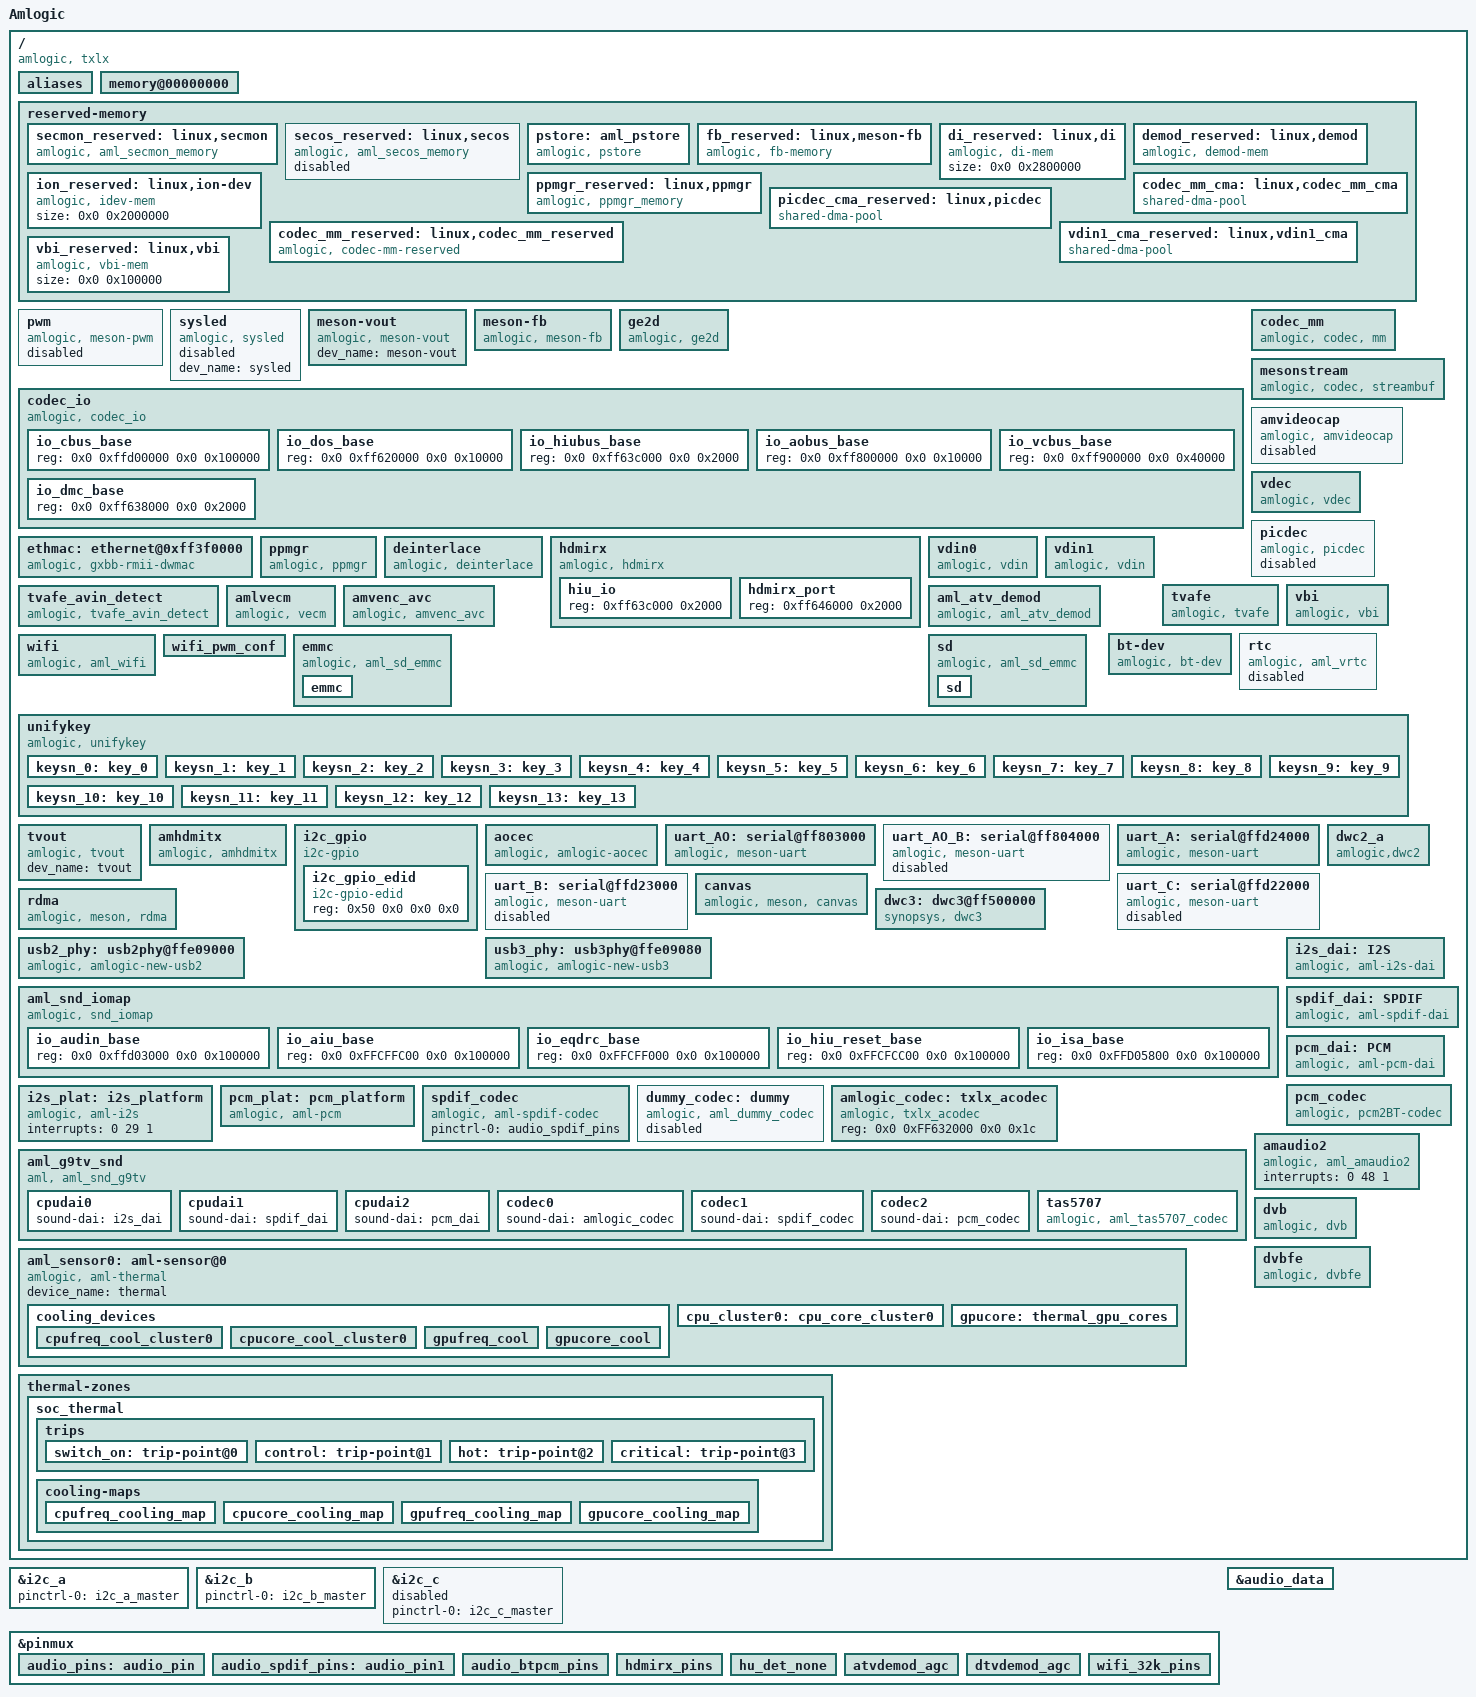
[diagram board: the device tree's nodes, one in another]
/*
 * arch/arm64/boot/dts/amlogic/txlx_t962e_r311.dts
 *
 * Copyright (C) 2017 Amlogic, Inc. All rights reserved.
 *
 * This program is free software; you can redistribute it and/or modify
 * it under the terms of the GNU General Public License as published by
 * the Free Software Foundation; either version 2 of the License, or
 * (at your option) any later version.
 *
 * This program is distributed in the hope that it will be useful, but WITHOUT
 * ANY WARRANTY; without even the implied warranty of MERCHANTABILITY or
 * FITNESS FOR A PARTICULAR PURPOSE.  See the GNU General Public License for
 * more details.
 *
*/

/dts-v1/;

#include <dt-bindings/interrupt-controller/arm-gic.h>
#include <dt-bindings/clock/txlx.h>
#include <dt-bindings/gpio/txlx.h>
#include <dt-bindings/gpio/gpio.h>
#include <dt-bindings/reset/aml_txlx.h>
#include <dt-bindings/pwm/pwm.h>
#include <dt-bindings/pwm/meson.h>

#include "mesontxlx.dtsi"
#include "partition_tv.dtsi"

/ {
	model = "Amlogic";
	compatible = "amlogic, txlx";
	interrupt-parent = <&gic>;
	#address-cells = <2>;
	#size-cells = <2>;

	aliases {
		serial0 = &uart_AO;
		serial1 = &uart_A;
		serial2 = &uart_B;
		serial3 = &uart_C;
		serial4 = &uart_AO_B;
	};

	memory@00000000 {
		device_type = "memory";
		linux,usable-memory = <0x0 0x100000 0x0 0x7ff00000>;
	};

	reserved-memory {
		#address-cells = <2>;
		#size-cells = <2>;
		ranges;
		/* global autoconfigured region for contiguous allocations */
		secmon_reserved:linux,secmon {
			compatible = "amlogic, aml_secmon_memory";
			reg = <0x0 0x10000000 0x0 0x200000>;
			no-map;
		};

		secos_reserved:linux,secos {
			status = "disable";
			compatible = "amlogic, aml_secos_memory";
			reg = <0x0 0x05300000 0x0 0x2000000>;
			no-map;
		};

		pstore:aml_pstore {
			compatible = "amlogic, pstore";
			reg = <0x0 0x07300000 0x0 0x100000>;
			no-map;
		};

		fb_reserved:linux,meson-fb {
			compatible = "amlogic, fb-memory";
			size = <0x0 0x2000000>;
			no-map;
		};
		/*di reserved mem*/
		di_reserved:linux,di {
			compatible = "amlogic, di-mem";
			/* buffer_size = 3621952(yuv422 8bit) | 4736064(yuv422 10bit) | 4179008(yuv422 10bit full pack mode) */
			/** 10x3621952=34.6M(0x23) support 8bit **/
			/** 10x4736064=45.2M(0x2e) support 12bit **/
			/** 10x4179008=40M(0x28) support 10bit **/
			size = <0x0 0x2800000>;
			//no-map;
		};
		/*di CMA pool */
		//di_cma_reserved:linux,di_cma {
			//compatible = "shared-dma-pool";
			//reusable;
			/* buffer_size = 3621952(yuv422 8bit) | 4736064(yuv422 10bit) | 4179008(yuv422 10bit full pack mode) */
			/** 10x3621952=34.6M(0x23) support 8bit **/
			/** 10x4736064=45.2M(0x2e) support 12bit **/
			/** 10x4179008=40M(0x28) support 10bit **/
			//size = <0x0 0x02800000>;
			//alignment = <0x0 0x400000>;
		//};
		demod_reserved:linux,demod {
			compatible = "amlogic, demod-mem";
			size = <0x0 0x600000>; //20m
			multi-use;
			//no-map;
		};

		ion_reserved:linux,ion-dev {
			compatible = "amlogic, idev-mem";
			size = <0x0 0x2000000>;
		};

		/*  POST PROCESS MANAGER */
		ppmgr_reserved:linux,ppmgr {
			compatible = "amlogic, ppmgr_memory";
			size = <0x0 0x0>;
			multi-use;
		};

		codec_mm_cma:linux,codec_mm_cma {
			compatible = "shared-dma-pool";
			reusable;
			size = <0x0 0xbc00000>;
			alignment = <0x0 0x400000>;
			linux,contiguous-region;
		};

		picdec_cma_reserved:linux,picdec {
			compatible = "shared-dma-pool";
			reusable;
			size = <0x0 0x0>;
			alignment = <0x0 0x0>;
			linux,contiguous-region;
		};

		/* codec shared reserved */
		codec_mm_reserved:linux,codec_mm_reserved {
			compatible = "amlogic, codec-mm-reserved";
			size = <0x0 0x4100000>;
			alignment = <0x0 0x100000>;
 			//no-map;
		};
		/*  vdin0 CMA pool */
		//vdin0_cma_reserved:linux,vdin0_cma {
		//	compatible = "shared-dma-pool";
		//	linux,phandle = <4>;
		//	reusable;
			/* 3840x2160x2x4  =64+4 M */
		//	size = <0x0 0x04400000>;
		//	alignment = <0x0 0x400000>;
		//};
		/*  vdin1 CMA pool */
		vdin1_cma_reserved:linux,vdin1_cma {
			compatible = "shared-dma-pool";
			linux,phandle = <5>;
			reusable;
			/* 1920x1080x2x4  =16+4 M */
			size = <0x0 0x01400000>;
			alignment = <0x0 0x400000>;
		};
		/*  tvafe CMA pool */
		//tvafe_cma_reserved:linux,tvafe_cma {
		//	compatible = "shared-dma-pool";
		//	linux,phandle = <6>;
		//	reusable;
			/* 5 M */
		//	size = <0x0 0x00800000>;
		//	alignment = <0x0 0x400000>;
		//};
		/*vbi reserved mem*/
		vbi_reserved:linux,vbi {
			compatible = "amlogic, vbi-mem";
			size = <0x0 0x100000>;
		};
	};

	pwm {
		compatible = "amlogic, meson-pwm";
		status = "disabled";
		pwm-outputs 	= <PWM_A>,<PWM_B>,<PWM_C>,<PWM_D>,
			      	  <PWM_E>,<PWM_F>,<PWM_AO_A>,<PWM_AO_B>;
		pwm-outputs-new = <PWM_A>,<PWM_B>,<PWM_C>,<PWM_D>,
				  <PWM_E>,<PWM_F>,<PWM_AO_A>,<PWM_AO_B>,
			          <PWM_A2>,<PWM_B2>,<PWM_C2>,<PWM_D2>,
			          <PWM_E2>,<PWM_F2>,<PWM_AO_A2>,<PWM_AO_B2>;
		reg = <0x0 0xc1108550 0x0 0x30>,
		      <0x0 0xc8100550  0x0 0x10>;
		clocks = <&clock CLK_XTAL>,
			 <&clock CLK_VID_PLL>,
			 <&clock CLK_FPLL_DIV4>,
			 <&clock CLK_FPLL_DIV3>;
		clock-names = "xtal",
			      "vid_pll_clk",
			      "fclk_div4",
			      "fclk_div3";
		clock-select = <XTAL_CLK>,<XTAL_CLK>,<XTAL_CLK>,<XTAL_CLK>,
			       	   <XTAL_CLK>,<XTAL_CLK>,<XTAL_CLK>,<XTAL_CLK>;
		clock-select-new = <XTAL_CLK>,<XTAL_CLK>,<XTAL_CLK>,<XTAL_CLK>,
		                   <XTAL_CLK>,<XTAL_CLK>,<XTAL_CLK>,<XTAL_CLK>,
		                   <XTAL_CLK>,<XTAL_CLK>,<XTAL_CLK>,<XTAL_CLK>,
		                   <XTAL_CLK>,<XTAL_CLK>,<XTAL_CLK>,<XTAL_CLK>;
		                   /*all channels use the default clock source XTAL_CLK*/
		                   /*and you can shoose it in file dt-bindings/pwm/meson.h*/
	};

	sysled {
		compatible = "amlogic, sysled";
		dev_name = "sysled";
		status = "disable";
		//led_gpio = <&gpio GPIODV_24 GPIO_ACTIVE_LOW>;
	};

	meson-vout {
		compatible = "amlogic, meson-vout";
		dev_name = "meson-vout";
		status = "okay";
	};

	meson-fb {
		compatible = "amlogic, meson-fb";
		memory-region = <&fb_reserved>;
		dev_name = "meson-fb";
		status = "okay";
		interrupts = <0 3 1
			0 89 1>;
		interrupt-names = "viu-vsync", "rdma";
		mem_size = <0x01800000 0x00100000>; /* fb0/fb1 memory size */
		display_mode_default = "1080p60hz";
		scale_mode = <1>; /** 0:VPU free scale 1:OSD free scale 2:OSD super scale */
		display_size_default = <1920 1080 1920 3240 32>; //1920*1080*4*3 = 0x17BB000
		pxp_mode = <1>; /** 0:normal mode 1:pxp mode */
	};

	ge2d {
		compatible = "amlogic, ge2d";
		dev_name = "ge2d";
		status = "okay";
		interrupts = <0 150 1>;
		interrupt-names = "ge2d";
		clocks = <&clock CLK_VAPB_0>,
			<&clock CLK_GE2D>;
		clock-names = "clk_vapb_0",
				"clk_ge2d";
		resets = <&clock GCLK_IDX_GE2D>;
		reset-names = "ge2d";
		reg = <0x0 0xff940000 0x0 0x10000>;
	};

	codec_io {
		compatible = "amlogic, codec_io";
		status = "okay";
		#address-cells=<2>;
		#size-cells=<2>;
		ranges;
		io_cbus_base{
			reg = <0x0 0xffd00000 0x0 0x100000>;
		};
		io_dos_base{
			reg = <0x0 0xff620000 0x0 0x10000>;
		};
		io_hiubus_base{
			reg = <0x0 0xff63c000 0x0 0x2000>;
		};
		io_aobus_base{
			reg = <0x0 0xff800000 0x0 0x10000>;
		};
		io_vcbus_base{
			reg = <0x0 0xff900000 0x0 0x40000>;
		};
		io_dmc_base{
			reg = <0x0 0xff638000 0x0 0x2000>;
		};
	};

	codec_mm {
			compatible = "amlogic, codec, mm";
			memory-region = <&codec_mm_cma &codec_mm_reserved>;
			dev_name = "codec_mm";
			status = "okay";
	};

	ethmac: ethernet@0xff3f0000 {
			compatible = "amlogic, gxbb-rmii-dwmac";
			reg = <0x0 0xff3f0000 0x0 0x10000
			0x0 0xff634540 0x0 0x8
			0x0 0xff634558 0x0 0xc>;
			interrupts = <0 8 1
						  0 9 1>;
			phy-mode= "rmii";
			mc_val = <0x1804>;
			resets = <&clock GCLK_IDX_ETHERNET>;
			reset-names = "ethpower";
			interrupt-names = "macirq",
							  "phyirq";
			clocks = <&clock CLK_81>;
			clock-names = "ethclk81";
			internal_phy=<1>;
			wol=<0>;
	};
	mesonstream {
		compatible = "amlogic, codec, streambuf";
		dev_name = "mesonstream";
		status = "okay";
		resets = <&clock GCLK_IDX_U_PARSER_TOP
			&clock GCLK_IDX_VPU_INTR
			&clock GCLK_IDX_DEMUX
			&clock GCLK_IDX_DOS>;
		reset-names = "parser_top",
			"vpu_intr",
			"demux",
			"vdec";
	};

	amvideocap {
		compatible = "amlogic, amvideocap";
		dev_name = "amvideocap.0";
		status = "disabled";
		max_size = <8>;//8M
	};

	vdec {
		compatible = "amlogic, vdec";
		dev_name = "vdec.0";
		status = "okay";
		interrupts = <0 3 1
			0 23 1
			0 32 1
			0 43 1
			0 44 1
			0 45 1>;
		interrupt-names = "vsync",
			"demux",
			"parser",
			"mailbox_0",
			"mailbox_1",
			"mailbox_2";
	};

	picdec {
		   compatible = "amlogic, picdec";
		   memory-region = <&picdec_cma_reserved>;
		   dev_name = "picdec";
		   status = "disabled";
	};

	ppmgr {
		compatible = "amlogic, ppmgr";//to match of_device_id's compatible member
		memory-region = <&ppmgr_reserved>;
		dev_name = "ppmgr";
		status = "okay";
	};

	deinterlace {
		compatible = "amlogic, deinterlace";
		status = "okay";
		flag_cma = <0>;/*0:use reserved;1:use cma*/
		memory-region = <&di_reserved>;
		//memory-region = <&di_cma_reserved>;
		interrupts = <0 46 1
				0 6 1>;
		interrupt-names = "de_irq",
				"timerc";
		clocks = <&clock CLK_FPLL_DIV4>,
			<&clock CLK_VPU_CLKB_TMP>,
			<&clock CLK_VPU_CLKB>;
		clock-names = "fclk_div4", "cts_vpu_clkb_tmp", "cts_vpu_clkb";
		/* nr_size(byte) = 1920*544*2(yuv422 8bit) | 2944*544*2*8(yuv422 10bit) | 2432*544*2(yuv422 10bit full pack mode) */
		/* mtn_size(byte) = 2048*544/2 */
		/* count_size(byte) = 2048*544/2 */
		/* mv_size(byte) = 1920*544*2/5 */
		/* mc_size(byte) = 544*2 */
		/* buffer_size = nr_size + mtn_size + count_size + mv_size + mc_size */
		/* buffer_size = 3621952(yuv422 8bit) | 4736064(yuv422 10bit) | 4179008(yuv422 10bit full pack mode) */
		buffer-size = <4179008>;
		hw-version = <2>;
		/* reserve-iomap = "true"; */
		/* if enable nr10bit, set nr10bit-surpport to 1 */
		nr10bit-surpport = <1>;
	};

	hdmirx {
		compatible = "amlogic, hdmirx";
		#address-cells=<1>;
		#size-cells=<1>;
		dev_name = "hdmirx";
		status = "okay";
		pinctrl-names = "hdmirx_pins","hu_det_none";
		pinctrl-0 = <&hdmirx_pins>;
		pinctrl-1 = <&hu_det_none>;
		rx_port_maps = <0x3120>;
		repeat = <0>;
		interrupts = <0 56 1>;
		clocks = <&clock CLK_HDMIRX_MODET_CLK>,
			   <&clock CLK_HDMIRX_CFG_CLK>,
			   <&clock CLK_HDMIRX_ACR_REF_CLK>,
			   <&clock CLK_HDMIRX_AUDMEAS_CLK>,
			   <&clock CLK_XTAL>,
			   <&clock CLK_FPLL_DIV5>,
			   <&clock CLK_AUD_PLL2FS>,
			   <&clock CLK_AUD_PLL4FS>,
			   <&clock CLK_AUD_OUT>;
		clock-names = "hdmirx_modet_clk",
					"hdmirx_cfg_clk",
					"hdmirx_acr_ref_clk",
					"hdmirx_audmeas_clk",
					"xtal",
					"fclk_div5",
					"hdmirx_aud_pll2fs",
					"hdmirx_aud_pll4f",
					"clk_aud_out";
		hdmirx_id = <0>;
		en_4k_2_2k = <0>;
		hiu_io{
			reg = <0xff63c000 0x2000>;
		};
		hdmirx_port{
			reg = <0xff646000 0x2000>;
		};
        };

	vdin0 {
		compatible = "amlogic, vdin";
		/*memory-region = <&vdin0_cma_reserved>;*/
		dev_name = "vdin0";
		status = "okay";
		reserve-iomap = "true";
		flag_cma = <1>;/*1:share with codec_mm;2:cma alone*/
		/*MByte, if 10bit disable: 64M(YUV422), if 10bit enable: 64*1.5 = 96M(YUV422)
		*if support 4K2K-YUV444-10bit-WR:3840*2160*4*4 ~= 128M
		*if support 4K2K-YUV422-10bit-wr:3840*2160*3*4 ~= 96M
		*if support 4K2K-YUV422-8BIT-WR:3840*2160*2*4 ~= 64M
		*if support 1080p-YUV422-8BIT-WR:1920*1080*2*4 ~= 16M*/
		cma_size = <96>;
		interrupts = <0 83 1>;
		rdma-irq = <2>;
		clocks = <&clock CLK_FPLL_DIV5>,
			<&clock CLK_VDIN_MEAS_CLK>;
		clock-names = "fclk_div5", "cts_vdin_meas_clk";
		vdin_id = <0>;
		/*vdin write mem color depth support:
		*bit0:support 8bit
		*bit1:support 9bit
		*bit2:support 10bit
		*bit3:support 12bit
		*bit4:support yuv422 10bit full pack mode (from txl new add)*/
		tv_bit_mode = <21>;
	};
	vdin1 {
		compatible = "amlogic, vdin";
		memory-region = <&vdin1_cma_reserved>;
		dev_name = "vdin1";
		status = "okay";
		reserve-iomap = "true";
		flag_cma = <0>;/*1:share with codec_mm;0:cma alone*/
		interrupts = <0 85 1>;
		rdma-irq = <4>;
		clocks = <&clock CLK_FPLL_DIV5>,
			<&clock CLK_VDIN_MEAS_CLK>;
		clock-names = "fclk_div5", "cts_vdin_meas_clk";
		vdin_id = <1>;
		/*vdin write mem color depth support:
		*bit0:support 8bit
		*bit1:support 9bit
		*bit2:support 10bit
		*bit3:support 12bit*/
		tv_bit_mode = <1>;
	};
	tvafe {
		compatible = "amlogic, tvafe";
		/*memory-region = <&tvafe_cma_reserved>;*/
		dev_name = "tvafe";
		status = "okay";
		flag_cma = <1>;/*1:share with codec_mm;0:cma alone*/
		cma_size = <5>;/*MByte*/
		reg = <0x0 0xff642000 0x0 0x2000>;/*tvafe reg base*/
		reserve-iomap = "true";
		tvafe_id = <0>;
		pinctrl-names = "default";
		tvafe_pin_mux = < /*!!particular sequence, no more and no less!!!*/
                        3       /*// TVAFE_CVBS_IN2,  //CVBS_IN0 = 0,*/
                        1       /*// TVAFE_CVBS_IN0,    //CVBS_IN1,*/
                        2       /*// TVAFE_CVBS_IN1,  //CVBS_IN2*/
                        4       /*// TVAFE_CVBS_IN3,    //CVBS_IN3,*/
		>;
	};
	vbi {
		compatible = "amlogic, vbi";
		memory-region = <&vbi_reserved>;
		dev_name = "vbi";
		status = "okay";
		interrupts = <0 83 1>;
		reserve-iomap = "true";
	};
	tvafe_avin_detect {
		compatible = "amlogic, tvafe_avin_detect";
		dev_name = "tvafe_avin_detect";
		status = "okay";
		device_mask = <1>;/*bit0:ch1;bit1:ch2*/
		interrupts = <0 12 1>,
						<0 13 1>;
	};
	amlvecm {
		compatible = "amlogic, vecm";
		dev_name = "aml_vecm";
		status = "okay";
		gamma_en = <1>;/*1:enabel ;0:disable*/
		wb_en = <1>;/*1:enabel ;0:disable*/
		cm_en = <1>;/*1:enabel ;0:disable*/
	};

	amvenc_avc {
		compatible = "amlogic, amvenc_avc";
		//memory-region = <&amvenc_avc_reserved>;
		//memory-region = <&avc_cma_reserved>;
		dev_name = "amvenc_avc";
		status = "okay";
		interrupts = <0 45 1>;
		interrupt-names = "mailbox_2";
	};

	aml_atv_demod {
		compatible = "amlogic, aml_atv_demod";
		dev_name = "aml_atv_demod";
		status = "okay";
		//pinctrl-names="atvdemod_agc";
		//pinctrl-0=<&atvdemod_agc>;
		reg = <0x0 0xff640000 0x0 0x2000
			   0x0 0xff648000 0x0 0x2000>;
		reg_23cf = <0x88188832>;/*default:0x88188832;r840 on haier:0x48188832*/
	};

	bt-dev{
		compatible = "amlogic, bt-dev";
		dev_name = "bt-dev";
		status = "okay";
		gpio_reset = <&gpio_ao GPIOAO_13 GPIO_ACTIVE_HIGH>;
		//gpio_en = <&gpio_ao GPIOAO_5 GPIO_ACTIVE_HIGH>;
	};

	rtc{
		compatible = "amlogic, aml_vrtc";
		alarm_reg_addr = <0xc81000a8>;
		timer_e_addr = <0xc1109988>;
		init_date = "2015/01/01";
		status = "disabled";
	};

	wifi {
		compatible = "amlogic, aml_wifi";
		dev_name = "aml_wifi";
		status = "okay";
		interrupt_pin = <&gpio_ao       GPIOAO_4       GPIO_ACTIVE_HIGH>;
		interrupts = <	0 68 4>;
		irq_trigger_type = "GPIO_IRQ_HIGH";
		dhd_static_buf;
		power_on_pin = <&gpio_ao       GPIOAO_5       GPIO_ACTIVE_HIGH>;
		pinctrl-names = "wifi_32k_pins";/*done*/
		pinctrl-0 = <&wifi_32k_pins>;
		pwm_config = <&wifi_pwm_conf>;
	};

 	wifi_pwm_conf:wifi_pwm_conf{
		pwm_channel1 = <PWM_D>;/*change it actually*/
		pwm_channel2 = <PWM_D2>;
		pwm_channel1_conf = <30541 15270 6>;
		pwm_channel2_conf = <30518 15259 9>;
	};

	emmc {
		compatible = "amlogic, aml_sd_emmc";
		dev_name = "aml_newsd.0";
		status = "okay";
		reg = <0x0 0xFFE07000 0x0 0x2000>;
		interrupts = <	0 218 1>;
		pinctrl-names = "emmc_clk_cmd_pins", "emmc_all_pins";
		pinctrl-0 = <&emmc_clk_cmd_pins>;
		pinctrl-1 = <&emmc_conf_pull_up &emmc_conf_pull_done &emmc_all_pins>;
		emmc {
			status = "okay";
			pinname = "emmc";
			ocr_avail = <0x200080>; /**VDD voltage 3.3 ~ 3.4 */
			caps = "MMC_CAP_8_BIT_DATA","MMC_CAP_MMC_HIGHSPEED",
				"MMC_CAP_SD_HIGHSPEED", "MMC_CAP_NONREMOVABLE","MMC_CAP_1_8V_DDR",
				"MMC_CAP_HW_RESET", "MMC_CAP_ERASE", "MMC_CAP_CMD23";
			/*caps2 = "MMC_CAP2_HS200", "MMC_CAP2_HS400";*/
			f_min = <300000>;
			f_max = <50000000>;
			base =  <0xff634400>;
			max_req_size = <0x20000>; /* 256KB */
			gpio_dat3 = <&gpio BOOT_3 GPIO_ACTIVE_HIGH>;
			hw_reset =  <&gpio BOOT_9 GPIO_ACTIVE_HIGH>;
			card_type = <1>; /* 1:mmc card(include eMMC), 2:sd card(include tSD), */
		};
	};

	sd {
		compatible = "amlogic, aml_sd_emmc";
		dev_name = "aml_newsd.0";
		status = "okay";/* not support*/
		reg = <0x0 0xFFE05000 0x0 0x2000>;
		interrupts = <0 217 1>;
		pinctrl-names = "sd_clk_cmd_pins", "sd_all_pins";
		pinctrl-0 = <&sd_clk_cmd_pins>;
		pinctrl-1 = <&sd_all_pins>;
		sd {
			status = "okay";
	   		pinname = "sd";
	   		ocr_avail = <0x00200080>; // 3.3:0x200000, 1.8+3.3:0x00200080
	   		caps = "MMC_CAP_4_BIT_DATA","MMC_CAP_MMC_HIGHSPEED","MMC_CAP_NONREMOVABLE",
	   			"MMC_CAP_SD_HIGHSPEED",
	   			//"MMC_CAP_UHS_SDR12",
	   			//"MMC_CAP_UHS_SDR25",
	   			//"MMC_CAP_UHS_SDR50",
	   			"MMC_CAP_UHS_SDR104";
	   		f_min = <400000>;
	   		f_max = <100000000>;
			base =  <0xff634400>;
	   		max_req_size = <0x20000>; /**128KB*/
	   		card_type = <3>; /* 0:unknown, 1:mmc card(include eMMC), 2:sd card(include tSD), 3:sdio device(ie:sdio-wifi), 4:SD combo (IO+mem) card, 5:NON sdio device(means sd/mmc card), other:reserved */
		};
	};

	unifykey {
		compatible = "amlogic, unifykey";
		status = "okay";

		unifykey-num = <14>;
		unifykey-index-0 = <&keysn_0>;
		unifykey-index-1 = <&keysn_1>;
		unifykey-index-2 = <&keysn_2>;
		unifykey-index-3 = <&keysn_3>;
		unifykey-index-4 = <&keysn_4>;
		unifykey-index-5 = <&keysn_5>;
		unifykey-index-6 = <&keysn_6>;
		unifykey-index-7 = <&keysn_7>;
		unifykey-index-8 = <&keysn_8>;
		unifykey-index-9 = <&keysn_9>;
		unifykey-index-10= <&keysn_10>;
		unifykey-index-11 = <&keysn_11>;
		unifykey-index-12 = <&keysn_12>;
		unifykey-index-13 = <&keysn_13>;

                keysn_0: key_0{
			key-name = "usid";
			key-device = "normal";
			key-permit = "read","write","del";
		};
		keysn_1:key_1{
			key-name = "mac";
                        key-device  = "normal";
			key-permit = "read","write","del";
		};
		keysn_2:key_2{
                        key-name = "hdcp";
			key-device = "secure";
                        key-type  = "sha1";
			key-permit = "read","write","del";
		};
		keysn_3:key_3{
			key-name = "secure_boot_set";
			key-device = "efuse";
			key-permit = "write";
		};
		keysn_4:key_4{
			key-name = "mac_bt";
			key-device = "normal";
			key-permit = "read","write","del";
                        key-type  = "mac";
		};
		keysn_5:key_5{
			key-name = "mac_wifi";
			key-device = "normal";
			key-permit = "read","write","del";
                        key-type  = "mac";
		};
		keysn_6:key_6{
			key-name = "hdcp2_tx";
			key-device = "normal";
			key-permit = "read","write","del";
		};
		keysn_7:key_7{
			key-name = "hdcp2_rx";
			key-device = "normal";
			key-permit = "read","write","del";
		};
		keysn_8:key_8{
			key-name = "widevinekeybox";
			key-device = "secure";
			key-type = "sha1";
			key-permit = "read","write","del";
		};
		keysn_9:key_9{
			key-name = "deviceid";
			key-device = "normal";
			key-permit = "read","write","del";
		};
		keysn_10:key_10{
			key-name = "hdcp22_fw_private";
			key-device = "secure";
			key-permit = "read","write","del";
		};
		keysn_11:key_11{
			key-name = "hdcp22_rx_private";
			key-device = "secure";
			key-permit = "read","write","del";
		};
		keysn_12:key_12{
			key-name = "hdcp22_rx_fw";
			key-device = "normal";
			key-permit = "read","write","del";
		};
		keysn_13:key_13{
			key-name = "hdcp14_rx";
			key-device = "normal";
			key-type  = "sha1";
			key-permit = "read","write","del";
		};
        };//End unifykey

	tvout {
		compatible = "amlogic, tvout";
		dev_name = "tvout";
		status = "okay";
	};

	amhdmitx: amhdmitx {
		compatible = "amlogic, amhdmitx";
		dev_name = "amhdmitx";
		status = "okay";
		pinctrl-names="hdmitx_hpd", "hdmitx_ddc";
		pinctrl-0=<&hdmitx_hpd>;
		pinctrl-1=<&hdmitx_ddc>;
		/* HPD, 57 + 32 = 89; CEC, 151 + 32 = 183*/
		interrupts = <0 57 1>;
		interrupt-names = "hdmitx_hpd";
		gpio_i2c_en = <0x1>;
		#address-cells = <2>;
		#size-cells = <2>;
		ranges;
	};

	i2c_gpio: i2c_gpio {
		compatible = "i2c-gpio";
		dev_name = "i2c-gpio";
		i2c-gpio,delay-us = <10>; /* 50 kHz */
		gpios = <&gpio GPIOH_2 0
			&gpio GPIOH_3 0>;
		#address-cells = <2>;
		#size-cells = <2>;
		i2c-gpio,timeout-ms = <10>;
		i2c_gpio_edid: i2c_gpio_edid {
			compatible = "i2c-gpio-edid";
			reg = <0x50 0x0 0x0 0x0>;
		};
	};

	aocec: aocec {
		compatible = "amlogic, amlogic-aocec";
		device_name = "aocec";
		status = "okay";
		vendor_name = "Amlogic"; /* Max Chars: 8     */
		vendor_id = <0x000000>; /* Refer to http://standards.ieee.org/develop/regauth/oui/oui.txt   */
		product_desc = "TXLX"; /* Max Chars: 16    */
		cec_osd_string = "AML_TV"; /* Max Chars: 14    */
		port_num = <3>;
		ee_cec;
		arc_port_mask = <0x2>;
		interrupts = <0 205 1>;
		interrupt-names = "hdmi_aocecb";
		pinctrl-names = "hdmitx_aocecb";
		pinctrl-0=<&hdmitx_aocecb>;
		reg = <0x0 0xFF800000 0x0 0x4
		       0x0 0xFF800000 0x0 0x400>;
	};

	uart_AO: serial@ff803000 {
		compatible = "amlogic, meson-uart";
		reg = <0x0 0xff803000 0x0 0x18>;
		interrupts = <0 193 1>;
		status = "okay";
		clocks = <&clock CLK_XTAL>;
		clock-names = "clk_uart";
		xtal_tick_en = <1>;
		fifosize = < 64 >;
		pinctrl-names = "default";
		pinctrl-0 = <&uart_ao_a_pins>;
		support-sysrq = <0>;	/* 0 not support , 1 support */
	};
	uart_AO_B: serial@ff804000 {
		compatible = "amlogic, meson-uart";
		reg = <0x0 0xff804000 0x0 0x18>;
		interrupts = <0 197 1>;
		status = "disabled";
		clocks = <&clock CLK_XTAL>;
		clock-names = "clk_uart";
		fifosize = < 64 >;
		pinctrl-names = "default";
		pinctrl-0 = <&uart_ao_b_2_pins>;
	};
	uart_A: serial@ffd24000 {
		compatible = "amlogic, meson-uart";
		reg = <0x0 0xffd24000 0x0 0x18>;
		interrupts = <0 26 1>;
		status = "okay";
		clocks = <&clock CLK_XTAL>;
		clock-names = "clk_uart";
		fifosize = < 128 >;
		pinctrl-names = "default";
		pinctrl-0 = <&uart_a_pins>;
		resets = <&clock GCLK_IDX_UART0>;
	};
	uart_B: serial@ffd23000 {
		compatible = "amlogic, meson-uart";
		reg = <0x0 0xffd23000 0x0 0x18>;
		interrupts = <0 75 1>;
		status = "disabled";
		clocks = <&clock CLK_XTAL>;
		clock-names = "clk_uart";
		fifosize = < 64 >;
		pinctrl-names = "default";
		pinctrl-0 = <&uart_b_pins>;
		resets = <&clock GCLK_IDX_UART1>;
	};
	uart_C: serial@ffd22000 {
		compatible = "amlogic, meson-uart";
		reg = <0x0 0xffd22000 0x0 0x18>;
		interrupts = <0 93 1>;
		status = "disabled";
		clocks = <&clock CLK_XTAL>;
		clock-names = "clk_uart";
		fifosize = < 64 >;
		pinctrl-names = "default";
		pinctrl-0 = <&uart_c_pins>;
		resets = <&clock GCLK_IDX_UART2>;
	};

	canvas{
		compatible = "amlogic, meson, canvas";
		dev_name = "amlogic-canvas";
		status = "okay";
		reg = <0x0 0xff638000 0x0 0x2000>;
	};

	rdma{
		compatible = "amlogic, meson, rdma";
		dev_name = "amlogic-rdma";
		status = "okay";
		interrupts = <0 89 1>;
		interrupt-names = "rdma";
	};

	dwc3: dwc3@ff500000 {
		compatible = "synopsys, dwc3";
		status = "okay";
		reg = <0x0 0xff500000 0x0 0x100000>;
		interrupts = <0 30 4>;
		usb-phy = <&usb2_phy>, <&usb3_phy>;
		cpu-type = "gxl";
		clock-src = "usb3.0";
	};

	usb2_phy: usb2phy@ffe09000 {
		compatible = "amlogic, amlogic-new-usb2";
		status = "okay";
		portnum = <4>;
		reg = <0x0 0xffe09000 0x0 0x80>;
	};

	usb3_phy: usb3phy@ffe09080 {
		compatible = "amlogic, amlogic-new-usb3";
		status = "okay";
		portnum = <0>;
		reg = <0x0 0xffe09080 0x0 0x20>;
	};

	dwc2_a {
		compatible = "amlogic,dwc2";
		device_name = "dwc2_a";
		reg = <0x0 0xff400000 0x0 0x40000>;
		status = "okay";
		interrupts = <0 31 4>;
		pl-periph-id = <0>; /** lm name */
		clock-src = "usb0"; /** clock src */
		port-id = <0>;  /** ref to mach/usb.h */
		port-type = <2>;        /** 0: otg, 1: host, 2: slave */
		port-speed = <0>; /** 0: default, high, 1: full */
		port-config = <0>; /** 0: default */
		port-dma = <0>; /** 0: default, 1: single, 2: incr, 3: incr4, 4: incr8, 5: incr16, 6: disable*/
		port-id-mode = <0>; /** 0: hardware, 1: sw_host, 2: sw_slave*/
		usb-fifo = <728>;
		cpu-type = "gxl";
		controller-type = <1>; /** 0: normal, 1: otg+dwc3 host only, 2: otg+dwc3 device only*/
		phy-reg = <0xffe09000>;
		phy-reg-size = <0xa0>;
		resets = <&clock GCLK_IDX_USB_GENERAL
					&clock GCLK_IDX_MISC_USB1_TO_DDR>;
		reset-names = "usb_general",
						"usb1_to_ddr";
	};

	/* Sound iomap */
	aml_snd_iomap {
		compatible = "amlogic, snd_iomap";
		status = "okay";
		#address-cells=<2>;
		#size-cells=<2>;
		ranges;
		io_audin_base {
			reg = <0x0 0xffd03000 0x0 0x100000>;
		};
		io_aiu_base {
			reg = <0x0 0xFFCFFC00 0x0 0x100000>;
		};
		io_eqdrc_base {
			reg = <0x0 0xFFCFF000 0x0 0x100000>;
		};
		io_hiu_reset_base {
			reg = <0x0 0xFFCFCC00 0x0 0x100000>;
		};
		io_isa_base {
			reg = <0x0 0xFFD05800 0x0 0x100000>;
		};
	};
	/* AUDIO MESON8 DEVICES */
	i2s_dai: I2S {
		#sound-dai-cells = <0>;
		resets = <
			&clock GCLK_IDX_AIU_AI_TOP_GLUE
			&clock GCLK_IDX_AIU_I2S_OUT
			&clock GCLK_IDX_AIU_AMCLK_MEASURE
			&clock GCLK_IDX_AIU_AIFIFO2
			&clock GCLK_IDX_AIU_AUD_MIXER
			&clock GCLK_IDX_AIU_MIXER_REG
			&clock GCLK_IDX_AIU_ADC
			&clock GCLK_IDX_AIU_TOP_LEVEL
			&clock GCLK_IDX_AIU_AOCLK
			&clock GCLK_IDX_AUD_IN
		>;
		reset-names =
			"top_glue",
			"i2s_out",
			"amclk_measure",
			"aififo2",
			"aud_mixer",
			"mixer_reg",
			"adc",
			"top_level",
			"aoclk",
			"aud_in";
		clocks = <&clock CLK_MPLL2>,
			<&clock CLK_AMCLK>;
		clock-names = "mpll2", "mclk";
		compatible = "amlogic, aml-i2s-dai";
	};
	spdif_dai: SPDIF {
		#sound-dai-cells = <0>;
		compatible = "amlogic, aml-spdif-dai";
		resets = <
			&clock GCLK_IDX_AIU_IEC958
			&clock GCLK_IDX_AIU_ICE958_AMCLK
		>;
		reset-names =
			"iec958",
			"iec958_amclk";
		clocks = <&clock CLK_MPLL1>,
			<&clock CLK_I958>,
			<&clock CLK_AMCLK>,
			<&clock CLK_SPDIF>,
			<&clock CLK_81>;
		clock-names = "mpll1", "i958", "mclk", "spdif", "clk_81";
	};
	pcm_dai: PCM {
		#sound-dai-cells = <0>;
		compatible = "amlogic, aml-pcm-dai";
		pinctrl-names = "aml_audio_btpcm";
		/* disable pcm pin mux temporary, enable it if necessary */
		/*pinctrl-0 = <&audio_btpcm_pins>;*/
		clocks = <&clock CLK_MPLL0>,
			<&clock CLK_PCM_MCLK>,
			<&clock CLK_PCM_SCLK>;
		clock-names = "mpll0", "pcm_mclk", "pcm_sclk";
		pcm_mode = <1>;	/* 0=slave mode, 1=master mode */
	};
	i2s_plat: i2s_platform {
		compatible = "amlogic, aml-i2s";
		interrupts = <0 29 1>;
	};
	pcm_plat: pcm_platform {
		compatible = "amlogic, aml-pcm";
	};
	spdif_codec: spdif_codec{
		#sound-dai-cells = <0>;
		compatible = "amlogic, aml-spdif-codec";
		pinctrl-names = "aml_audio_spdif";
		pinctrl-0 = <&audio_spdif_pins>;
	};
	pcm_codec: pcm_codec{
		#sound-dai-cells = <0>;
		compatible = "amlogic, pcm2BT-codec";
	};
	/* endof AUDIO MESON8 DEVICES */

	/* AUDIO board specific */
	dummy_codec:dummy{
		#sound-dai-cells = <0>;
		compatible = "amlogic, aml_dummy_codec";
		status = "disabled";
	};

	amlogic_codec:txlx_acodec{
		#sound-dai-cells = <0>;
		compatible = "amlogic, txlx_acodec";
		reg = <0x0 0xFF632000 0x0 0x1c>;
		status = "okay";
	};
	aml_g9tv_snd {
		compatible = "aml, aml_snd_g9tv";
		status = "okay";
		aml-sound-card,format = "i2s";
		aml_sound_card,name = "AML-G9TVAUDIO";
		pinctrl-names = "aml_snd_g9tv";
		pinctrl-0 = <&audio_pins>;
		/*avout mute gpio*/
		mute_gpio-gpios = <&gpio GPIOZ_7 GPIO_ACTIVE_HIGH>;
		/*analog amp mute*/
		/*amp_mute_gpio-gpios = <&gpio GPIOZ_18 GPIO_ACTIVE_LOW>;*/
		aux_dev = "tas5707";
		cpu_list = <&cpudai0 &cpudai1 &cpudai2>;
		codec_list = <&codec0 &codec1 &codec2>;
		plat_list = <&i2s_plat &i2s_plat &pcm_plat>;
		cpudai0: cpudai0 {
			sound-dai = <&i2s_dai>;
		};
		cpudai1: cpudai1 {
			sound-dai = <&spdif_dai>;
		};
		cpudai2: cpudai2 {
			sound-dai = <&pcm_dai>;
		};
		codec0: codec0 {
			sound-dai = <&amlogic_codec>;
		};
		codec1: codec1 {
			sound-dai = <&spdif_codec>;
		};
		codec2: codec2 {
			sound-dai = <&pcm_codec>;
		};
		tas5707 {
			compatible = "amlogic, aml_tas5707_codec";
			codec_name = "tas5707";
			status = "okay";
			i2c_addr = <0x1B>;
			i2c_bus = "i2c_bus_a";
			reset_pin = <&gpio GPIOZ_13 GPIO_ACTIVE_LOW>;
		};
 	};
	amaudio2 {
		compatible = "amlogic, aml_amaudio2";
		status = "okay";
		interrupts = <0 48 1>;
 	};

	dvb {
		compatible = "amlogic, dvb";
		dev_name = "dvb";
		status = "okay";
		/*"parallel","serial","disable"*/
		ts2 = "parallel";
		ts2_control = <0>;
		ts2_invert = <0>;
		resets = <&clock GCLK_IDX_DEMUX
				&clock GCLK_IDX_ASYNC_FIFO
				&clock GCLK_IDX_AHB_ARB0
				&clock GCLK_IDX_U_PARSER_TOP>;
		reset-names = "demux", "asyncfifo", "ahbarb0", "uparsertop";
	};

	aml_sensor0: aml-sensor@0 {
		compatible = "amlogic, aml-thermal";
		status = "okay";
		device_name = "thermal";
		#thermal-sensor-cells = <1>;
		cooling_devices {
			cpufreq_cool_cluster0 {
				min_state = <1000000>;
				dyn_coeff = <140>;
				cluster_id = <0>;
				node_name = "cpus";
				device_type = "cpufreq";
			};
			cpucore_cool_cluster0 {
				min_state = <1>;
				dyn_coeff = <0>;
				cluster_id = <0>;
				node_name = "cpu_core_cluster0";
				device_type = "cpucore";
			};
			gpufreq_cool {
				min_state = <400>;
				dyn_coeff = <437>;
				cluster_id = <0>;
				node_name = "mali";
				device_type = "gpufreq";
			};
			gpucore_cool {
				min_state = <1>;
				dyn_coeff = <0>;
				cluster_id = <0>;
				node_name = "thermal_gpu_cores";
				device_type = "gpucore";
			};
		};
		cpu_cluster0:cpu_core_cluster0 {
			#cooling-cells = <2>; /* min followed by max */
		};
		gpucore:thermal_gpu_cores {
			#cooling-cells = <2>; /* min followed by max */
		};
	};
	dvb {
		compatible = "amlogic, dvb";
		dev_name = "dvb";
		status = "okay";
		/*"parallel","serial","disable"*/
		ts2 = "parallel";
		ts2_control = <0>;
		ts2_invert = <0>;
		resets = <&clock GCLK_IDX_DEMUX
				&clock GCLK_IDX_ASYNC_FIFO
				&clock GCLK_IDX_AHB_ARB0
				&clock GCLK_IDX_U_PARSER_TOP>;
		reset-names = "demux", "asyncfifo", "ahbarb0", "uparsertop";
	};

	dvbfe {
		compatible = "amlogic, dvbfe";
		dev_name = "dvbfe";
		status = "okay";
		dtv_demod0 = "AMLDEMOD";
		fe0_dtv_demod = <0>;
		fe0_ts = <2>;
		fe0_dev = <0>;
		dtv_demod0_mem = <0>;
		dtv_demod0_spectrum = <1>;
		memory-region = <&demod_reserved>;
		tuner0 = "si2151_tuner";
		tuner0_i2c_adap_id = <2>;
		tuner0_i2c_addr = <0x60>;
		//tuner0_reset_value = <0>;
		//tuner0_reset_gpio =  "GPIOY_10" ;  /*GPIOX_8   76*/
		fe0_tuner = <0>;
		atv_demod0 = "aml_atv_demod";
		fe0_atv_demod = <0>;
	};

	thermal-zones {
		soc_thermal {
			polling-delay = <1000>;
			polling-delay-passive = <100>;
			sustainable-power = <2150>;

			thermal-sensors = <&aml_sensor0 3>;

			trips {
				switch_on: trip-point@0 {
					temperature = <70000>;
					hysteresis = <1000>;
					type = "passive";
				};
				control: trip-point@1 {
					temperature = <80000>;
					hysteresis = <1000>;
					type = "passive";
				};
				hot: trip-point@2 {
					temperature = <85000>;
					hysteresis = <5000>;
					type = "hot";
				};
				critical: trip-point@3 {
					temperature = <260000>;
					hysteresis = <1000>;
					type = "critical";
				};
			};

			cooling-maps {
				cpufreq_cooling_map {
					trip = <&control>;
					cooling-device = <&cpus 0 4>;
					contribution = <1024>;
				};
				cpucore_cooling_map {
					trip = <&control>;
					cooling-device = <&cpu_cluster0 0 3>;
					contribution = <1024>;
				};
				gpufreq_cooling_map {
					trip = <&control>;
					cooling-device = <&gpu 0 4>;
					contribution = <1024>;
				};
				gpucore_cooling_map {
					trip = <&control>;
					cooling-device = <&gpucore 0 2>;
					contribution = <1024>;
				};
			};
		};
	};

}; /* end of / */

&i2c_a {
	status = "okay";
	pinctrl-names="default";
	pinctrl-0=<&i2c_a_master>;
};

&i2c_b {
	status = "okay";
	pinctrl-names="default";
	pinctrl-0=<&i2c_b_master>;
};

&i2c_c {
	status = "disabled";
	pinctrl-names="default";
	pinctrl-0=<&i2c_c_master>;
};

&pinmux {
	audio_pins:audio_pin{
		amlogic,setmask=<4 0x00000780>;
		amlogic,clrmask=<3 0x001c0000
				 4 0x00000001>;
		amlogic,pins = "GPIOZ_10", "GPIOZ_11", "GPIOZ_12", "GPIOZ_14";
	};
	audio_spdif_pins:audio_pin1{
		amlogic,setmask=<3 0x40000000
						10 0x00800000>; /*spdif_out*/
		amlogic,clrmask=<9 0x09100000
						2 0x80000000>;
		amlogic,pins = "GPIOZ_17", "GPIOZ_18"; /*spdif_out*/
	};
	audio_btpcm_pins:audio_btpcm_pins{
		/* BT PCM PINMUX SETTING*/
		amlogic,setmask=<4 0x1e000>;
		amlogic,clrmask=<4 0xf3f00000>;
		amlogic,pins ="GPIOZ_0", "GPIOZ_1", "GPIOZ_2", "GPIOZ_3";
	};
	hdmirx_pins: hdmirx_pins {
		amlogic,setmask = <5  0xffff0000>;
		amlogic,clrmask = <5  0x0000ff00>;
		amlogic,pins = "GPIOW_6","GPIOW_8",
					"GPIOW_10","GPIOW_12",
					"GPIOW_14","GPIOW_16",
					"GPIOW_17","GPIOW_18","GPIOW_19","GPIOW_20";
	};
	hu_det_none: hu_det_none {
		amlogic,setmask = <5  0xffff0000>,
						<AO 0x1800>;
		amlogic,clrmask = <5  0x0000ff00>;
		amlogic,pins = "GPIOW_4";
	};
	atvdemod_agc: atvdemod_agc {
		amlogic,setmask=<2  0x800000>;
		amlogic,clrmask=<2  0x500000>;
		amlogic,pins="GPIODV_2";
	};
	dtvdemod_agc: dtvdemod_agc {
		amlogic,setmask=<2  0x400000>;
		amlogic,clrmask=<2  0x980000>;
		amlogic,pins="GPIODV_2";
	};
	wifi_32k_pins:wifi_32k_pins{
		amlogic,setmask=<2 0x100000>;
		amlogic,clrmask=<2  0x80c00000>,
						<9  0x2000000>;
		amlogic,pins="GPIODV_2";
	};
};

&audio_data{
	status = "okay";
};
